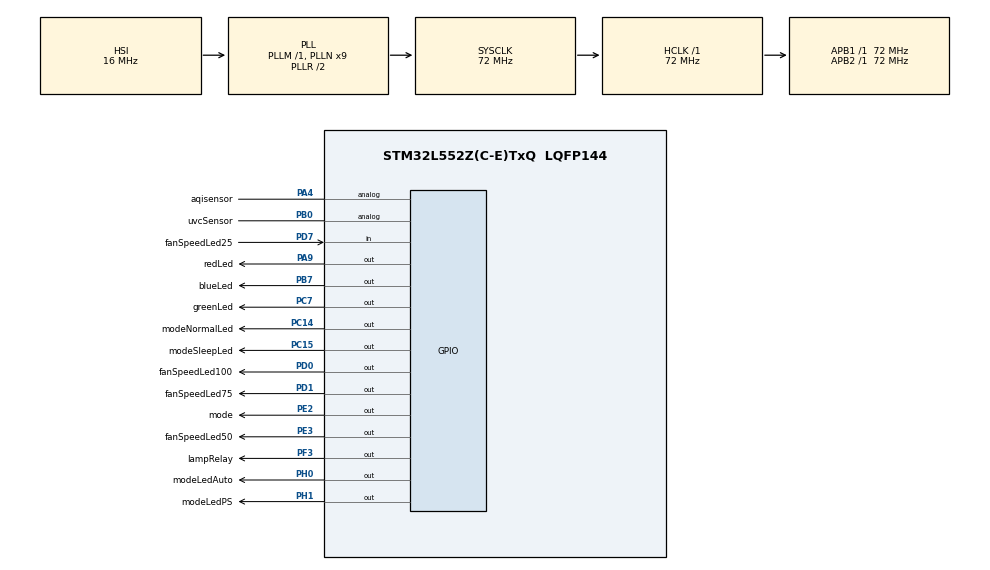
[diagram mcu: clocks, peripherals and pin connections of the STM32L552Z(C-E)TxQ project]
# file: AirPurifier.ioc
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Mcu.Family=STM32L5
Mcu.Name=STM32L552Z(C-E)TxQ
Mcu.Package=LQFP144
Mcu.TrustZone=disable
NVIC.PriorityGroup=NVIC_PRIORITYGROUP_3
PA13\ (JTMS/SWDIO).Mode=Serial_Wire
PA13\ (JTMS/SWDIO).Signal=DEBUG_JTMS-SWDIO
PA14\ (JTCK/SWCLK).Mode=Serial_Wire
PA14\ (JTCK/SWCLK).Signal=DEBUG_JTCK-SWCLK
PA4.GPIO_Label=aqisensor
PA4.Signal=GPIO_Analog
PA9.GPIO_Label=redLed
PA9.Signal=GPIO_Output
PB0.GPIO_Label=uvcSensor
PB0.Signal=GPIO_Analog
PB7.GPIO_Label=blueLed
PB7.Signal=GPIO_Output
PC14-OSC32_IN\ (PC14).GPIO_Label=modeNormalLed
PC14-OSC32_IN\ (PC14).Signal=GPIO_Output
PC15-OSC32_OUT\ (PC15).GPIO_Label=modeSleepLed
PC15-OSC32_OUT\ (PC15).Signal=GPIO_Output
PC7.GPIO_Label=greenLed
PC7.Signal=GPIO_Output
PD0.GPIO_Label=fanSpeedLed100
PD0.Signal=GPIO_Output
PD1.GPIO_Label=fanSpeedLed75
PD1.Signal=GPIO_Output
PD7.GPIO_Label=fanSpeedLed25
PD7.Signal=GPIO_Input
PE2.GPIO_Label=mode
PE2.Signal=GPIO_Output
PE3.GPIO_Label=fanSpeedLed50
PE3.Signal=GPIO_Output
PF3.GPIO_Label=lampRelay
PF3.Signal=GPIO_Output
PH0-OSC_IN\ (PH0).GPIO_Label=modeLedAuto
PH0-OSC_IN\ (PH0).Signal=GPIO_Output
PH1-OSC_OUT\ (PH1).GPIO_Label=modeLedPS
PH1-OSC_OUT\ (PH1).Signal=GPIO_Output
ProjectManager.HeapSize=0x200
ProjectManager.StackSize=0x400
ProjectManager.TargetToolchain=STM32CubeIDE
RCC.ADCCLockSelection=RCC_ADCCLKSOURCE_SYSCLK
RCC.ADCFreq_Value=72000000
RCC.AHBFreq_Value=72000000
RCC.APB1Freq_Value=72000000
RCC.APB1TimFreq_Value=72000000
RCC.APB2Freq_Value=72000000
RCC.APB2TimFreq_Value=72000000
RCC.CK48CLockSelection=RCC_USBCLKSOURCE_HSI48
RCC.CortexFreq_Value=72000000
RCC.HCLKFreq_Value=72000000
RCC.HSE_VALUE=16000000
RCC.HSI48_VALUE=48000000
RCC.HSI_VALUE=16000000
RCC.LSE_VALUE=32768
RCC.MSI_VALUE=4000000
RCC.PLLN=9
RCC.PLLSAI1N=24
RCC.PLLSourceVirtual=RCC_PLLSOURCE_HSI
RCC.RTCClockSelection=RCC_RTCCLKSOURCE_HSE_DIV32
RCC.SYSCLKFreq_VALUE=72000000
RCC.SYSCLKSource=RCC_SYSCLKSOURCE_PLLCLK
RCC.USBFreq_Value=48000000
RCC.VCOOutputFreq_Value=144000000
VP_ICACHE_VS_ICACHE.Mode=DirectMappedCache
VP_PWR_VS_DBSignals.Mode=DisableDeadBatterySignals
VP_PWR_VS_SECSignals.Mode=Security/Privilege
board=NUCLEO-L552ZE-Q

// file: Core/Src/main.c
/* USER CODE BEGIN Header */
/**
  ******************************************************************************
  * @file           : main.c
  * @brief          : Main program body
  ******************************************************************************
  * @attention
  *
  * Copyright (c) 2021 STMicroelectronics.
  * All rights reserved.
  *
  * This software is licensed under terms that can be found in the LICENSE file
  * in the root directory of this software component.
  * If no LICENSE file comes with this software, it is provided AS-IS.
  *
  ******************************************************************************
  */
/* USER CODE END Header */
#include "main.h"

/* USER CODE BEGIN Includes */

#include "Header.h"

/* USER CODE END Includes */

void SystemClock_Config(void);
static void MX_GPIO_Init(void);
static void MX_ICACHE_Init(void);

int main(void)
{
  /* USER CODE BEGIN 1 */
	//Gpio_Name_t Led = {GPIOA, GPIO_PIN_9};

  /* USER CODE END 1 */

  /* MCU Configuration--------------------------------------------------------*/

  /* Reset of all peripherals, Initializes the Flash interface and the Systick. */
  HAL_Init();

  /* USER CODE BEGIN Init */
    gpioInit();

  /* USER CODE END Init */

  /* Configure the system clock */
  SystemClock_Config();

  /* Initialize all configured peripherals */
  MX_GPIO_Init();
  MX_ICACHE_Init();

  /* Infinite loop */
  while (1)
  {

    /* USER CODE BEGIN 3 */
	  //HAL_GPIO_WritePin(Led.port, Led.pin,  GPIO_PIN_SET);
	  HAL_GPIO_TogglePin(greenLed.port, greenLed.pin);
	  HAL_GPIO_TogglePin(blueLed.port, blueLed.pin);
	  HAL_GPIO_TogglePin(redLed.port, redLed.pin);
	  HAL_Delay(50);

  }
  /* USER CODE END 3 */
}

void SystemClock_Config(void)
{
  RCC_OscInitTypeDef RCC_OscInitStruct = {0};
  RCC_ClkInitTypeDef RCC_ClkInitStruct = {0};

  /** Configure the main internal regulator output voltage
  */
  if (HAL_PWREx_ControlVoltageScaling(PWR_REGULATOR_VOLTAGE_SCALE1) != HAL_OK)
  {
    Error_Handler();
  }
  /** Initializes the RCC Oscillators according to the specified parameters
  * in the RCC_OscInitTypeDef structure.
  */
  RCC_OscInitStruct.OscillatorType = RCC_OSCILLATORTYPE_HSI;
  RCC_OscInitStruct.HSIState = RCC_HSI_ON;
  RCC_OscInitStruct.HSICalibrationValue = RCC_HSICALIBRATION_DEFAULT;
  RCC_OscInitStruct.PLL.PLLState = RCC_PLL_ON;
  RCC_OscInitStruct.PLL.PLLSource = RCC_PLLSOURCE_HSI;
  RCC_OscInitStruct.PLL.PLLM = 1;
  RCC_OscInitStruct.PLL.PLLN = 9;
  RCC_OscInitStruct.PLL.PLLP = RCC_PLLP_DIV7;
  RCC_OscInitStruct.PLL.PLLQ = RCC_PLLQ_DIV2;
  RCC_OscInitStruct.PLL.PLLR = RCC_PLLR_DIV2;
  if (HAL_RCC_OscConfig(&RCC_OscInitStruct) != HAL_OK)
  {
    Error_Handler();
  }
  /** Initializes the CPU, AHB and APB buses clocks
  */
  RCC_ClkInitStruct.ClockType = RCC_CLOCKTYPE_HCLK|RCC_CLOCKTYPE_SYSCLK
                              |RCC_CLOCKTYPE_PCLK1|RCC_CLOCKTYPE_PCLK2;
  RCC_ClkInitStruct.SYSCLKSource = RCC_SYSCLKSOURCE_PLLCLK;
  RCC_ClkInitStruct.AHBCLKDivider = RCC_SYSCLK_DIV1;
  RCC_ClkInitStruct.APB1CLKDivider = RCC_HCLK_DIV1;
  RCC_ClkInitStruct.APB2CLKDivider = RCC_HCLK_DIV1;

  if (HAL_RCC_ClockConfig(&RCC_ClkInitStruct, FLASH_LATENCY_3) != HAL_OK)
  {
    Error_Handler();
  }
}

static void MX_ICACHE_Init(void)
{

  /** Enable instruction cache in 1-way (direct mapped cache)
  */
  if (HAL_ICACHE_ConfigAssociativityMode(ICACHE_1WAY) != HAL_OK)
  {
    Error_Handler();
  }
  if (HAL_ICACHE_Enable() != HAL_OK)
  {
    Error_Handler();
  }

}

static void MX_GPIO_Init(void)
{
  GPIO_InitTypeDef GPIO_InitStruct = {0};

  /* GPIO Ports Clock Enable */
  __HAL_RCC_GPIOE_CLK_ENABLE();
  __HAL_RCC_GPIOC_CLK_ENABLE();
  __HAL_RCC_GPIOF_CLK_ENABLE();
  __HAL_RCC_GPIOH_CLK_ENABLE();
  __HAL_RCC_GPIOA_CLK_ENABLE();
  __HAL_RCC_GPIOB_CLK_ENABLE();
  __HAL_RCC_GPIOD_CLK_ENABLE();

  /*Configure GPIO pin Output Level */
  HAL_GPIO_WritePin(GPIOE, mode_Pin|fanSpeedLed50_Pin, GPIO_PIN_RESET);

  /*Configure GPIO pin Output Level */
  HAL_GPIO_WritePin(GPIOC, modeNormalLed_Pin|modeSleepLed_Pin|greenLed_Pin, GPIO_PIN_RESET);

  /*Configure GPIO pin Output Level */
  HAL_GPIO_WritePin(lampRelay_GPIO_Port, lampRelay_Pin, GPIO_PIN_RESET);

  /*Configure GPIO pin Output Level */
  HAL_GPIO_WritePin(GPIOH, modeLedAuto_Pin|modeLedPS_Pin, GPIO_PIN_RESET);

  /*Configure GPIO pin Output Level */
  HAL_GPIO_WritePin(redLed_GPIO_Port, redLed_Pin, GPIO_PIN_RESET);

  /*Configure GPIO pin Output Level */
  HAL_GPIO_WritePin(GPIOD, fanSpeedLed100_Pin|fanSpeedLed75_Pin, GPIO_PIN_RESET);

  /*Configure GPIO pin Output Level */
  HAL_GPIO_WritePin(blueLed_GPIO_Port, blueLed_Pin, GPIO_PIN_RESET);

  /*Configure GPIO pins : mode_Pin fanSpeedLed50_Pin */
  GPIO_InitStruct.Pin = mode_Pin|fanSpeedLed50_Pin;
  GPIO_InitStruct.Mode = GPIO_MODE_OUTPUT_PP;
  GPIO_InitStruct.Pull = GPIO_NOPULL;
  GPIO_InitStruct.Speed = GPIO_SPEED_FREQ_LOW;
  HAL_GPIO_Init(GPIOE, &GPIO_InitStruct);

  /*Configure GPIO pins : modeNormalLed_Pin modeSleepLed_Pin greenLed_Pin */
  GPIO_InitStruct.Pin = modeNormalLed_Pin|modeSleepLed_Pin|greenLed_Pin;
  GPIO_InitStruct.Mode = GPIO_MODE_OUTPUT_PP;
  GPIO_InitStruct.Pull = GPIO_NOPULL;
  GPIO_InitStruct.Speed = GPIO_SPEED_FREQ_LOW;
  HAL_GPIO_Init(GPIOC, &GPIO_InitStruct);

  /*Configure GPIO pin : lampRelay_Pin */
  GPIO_InitStruct.Pin = lampRelay_Pin;
  GPIO_InitStruct.Mode = GPIO_MODE_OUTPUT_PP;
  GPIO_InitStruct.Pull = GPIO_NOPULL;
  GPIO_InitStruct.Speed = GPIO_SPEED_FREQ_LOW;
  HAL_GPIO_Init(lampRelay_GPIO_Port, &GPIO_InitStruct);

  /*Configure GPIO pins : modeLedAuto_Pin modeLedPS_Pin */
  GPIO_InitStruct.Pin = modeLedAuto_Pin|modeLedPS_Pin;
  GPIO_InitStruct.Mode = GPIO_MODE_OUTPUT_PP;
  GPIO_InitStruct.Pull = GPIO_NOPULL;
  GPIO_InitStruct.Speed = GPIO_SPEED_FREQ_LOW;
  HAL_GPIO_Init(GPIOH, &GPIO_InitStruct);

  /*Configure GPIO pin : aqisensor_Pin */
  GPIO_InitStruct.Pin = aqisensor_Pin;
  GPIO_InitStruct.Mode = GPIO_MODE_ANALOG;
  GPIO_InitStruct.Pull = GPIO_NOPULL;
  HAL_GPIO_Init(aqisensor_GPIO_Port, &GPIO_InitStruct);

  /*Configure GPIO pin : uvcSensor_Pin */
  GPIO_InitStruct.Pin = uvcSensor_Pin;
  GPIO_InitStruct.Mode = GPIO_MODE_ANALOG;
  GPIO_InitStruct.Pull = GPIO_NOPULL;
  HAL_GPIO_Init(uvcSensor_GPIO_Port, &GPIO_InitStruct);

  /*Configure GPIO pin : redLed_Pin */
  GPIO_InitStruct.Pin = redLed_Pin;
  GPIO_InitStruct.Mode = GPIO_MODE_OUTPUT_PP;
  GPIO_InitStruct.Pull = GPIO_NOPULL;
  GPIO_InitStruct.Speed = GPIO_SPEED_FREQ_LOW;
  HAL_GPIO_Init(redLed_GPIO_Port, &GPIO_InitStruct);

  /*Configure GPIO pins : fanSpeedLed100_Pin fanSpeedLed75_Pin */
  GPIO_InitStruct.Pin = fanSpeedLed100_Pin|fanSpeedLed75_Pin;
  GPIO_InitStruct.Mode = GPIO_MODE_OUTPUT_PP;
  GPIO_InitStruct.Pull = GPIO_NOPULL;
  GPIO_InitStruct.Speed = GPIO_SPEED_FREQ_LOW;
  HAL_GPIO_Init(GPIOD, &GPIO_InitStruct);

  /*Configure GPIO pin : fanSpeedLed25_Pin */
  GPIO_InitStruct.Pin = fanSpeedLed25_Pin;
  GPIO_InitStruct.Mode = GPIO_MODE_INPUT;
  GPIO_InitStruct.Pull = GPIO_NOPULL;
  HAL_GPIO_Init(fanSpeedLed25_GPIO_Port, &GPIO_InitStruct);

  /*Configure GPIO pin : blueLed_Pin */
  GPIO_InitStruct.Pin = blueLed_Pin;
  GPIO_InitStruct.Mode = GPIO_MODE_OUTPUT_PP;
  GPIO_InitStruct.Pull = GPIO_NOPULL;
  GPIO_InitStruct.Speed = GPIO_SPEED_FREQ_LOW;
  HAL_GPIO_Init(blueLed_GPIO_Port, &GPIO_InitStruct);

}

void Error_Handler(void)
{
  __disable_irq();
  while (1)
  {
  }
}
